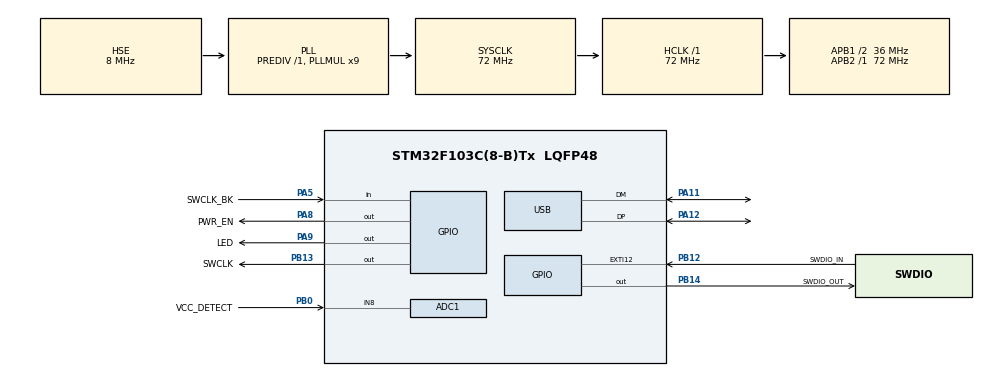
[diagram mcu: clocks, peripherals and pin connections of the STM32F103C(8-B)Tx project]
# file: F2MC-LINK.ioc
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ADC1.Channel-0\#ChannelRegularConversion=ADC_CHANNEL_8
ADC1.ContinuousConvMode=ENABLE
ADC1.NbrOfConversionFlag=1
ADC1.Rank-0\#ChannelRegularConversion=1
ADC1.SamplingTime-0\#ChannelRegularConversion=ADC_SAMPLETIME_71CYCLES_5
ADC1.master=1
Mcu.Family=STM32F1
Mcu.Name=STM32F103C(8-B)Tx
Mcu.Package=LQFP48
NVIC.EXTI15_10_IRQn=true\:0\:0\:false\:false\:true\:false\:true\:true\:true
NVIC.PriorityGroup=NVIC_PRIORITYGROUP_4
NVIC.USB_LP_CAN1_RX0_IRQn=true\:0\:0\:false\:false\:true\:false\:false\:true\:true
PA11.Mode=Device
PA11.Signal=USB_DM
PA12.Mode=Device
PA12.Signal=USB_DP
PA13.Mode=Serial_Wire
PA13.Signal=SYS_JTMS-SWDIO
PA14.Mode=Serial_Wire
PA14.Signal=SYS_JTCK-SWCLK
PA5.GPIO_Label=SWCLK_BK
PA5.Signal=GPIO_Input
PA8.GPIO_Label=PWR_EN
PA8.PinState=GPIO_PIN_RESET
PA8.Signal=GPIO_Output
PA9.GPIO_Label=LED
PA9.GPIO_Speed=GPIO_SPEED_FREQ_HIGH
PA9.Signal=GPIO_Output
PB0.GPIO_Label=VCC_DETECT
PB0.Signal=ADCx_IN8
PB12.GPIO_Label=SWDIO_IN
PB12.GPIO_ModeDefaultEXTI=GPIO_MODE_IT_FALLING
PB12.Signal=GPXTI12
PB13.GPIO_Label=SWCLK
PB13.GPIO_Speed=GPIO_SPEED_FREQ_HIGH
PB13.PinState=GPIO_PIN_SET
PB13.Signal=GPIO_Output
PB14.GPIO_Label=SWDIO_OUT
PB14.GPIO_Speed=GPIO_SPEED_FREQ_HIGH
PB14.PinState=GPIO_PIN_SET
PB14.Signal=GPIO_Output
PD0-OSC_IN.Mode=HSE-External-Oscillator
PD0-OSC_IN.Signal=RCC_OSC_IN
PD1-OSC_OUT.Mode=HSE-External-Oscillator
PD1-OSC_OUT.Signal=RCC_OSC_OUT
ProjectManager.HeapSize=0x200
ProjectManager.StackSize=0x400
ProjectManager.TargetToolchain=STM32CubeIDE
RCC.ADCPresc=RCC_ADCPCLK2_DIV6
RCC.AHBFreq_Value=72000000
RCC.APB1CLKDivider=RCC_HCLK_DIV2
RCC.APB1Freq_Value=36000000
RCC.APB1TimFreq_Value=72000000
RCC.APB2Freq_Value=72000000
RCC.APB2TimFreq_Value=72000000
RCC.HCLKFreq_Value=72000000
RCC.PLLMUL=RCC_PLL_MUL9
RCC.SYSCLKFreq_VALUE=72000000
RCC.SYSCLKSource=RCC_SYSCLKSOURCE_PLLCLK
RCC.USBFreq_Value=48000000
RCC.USBPrescaler=RCC_USBCLKSOURCE_PLL_DIV1_5
RealThread.X-CUBE-RT-Thread_Nano.4.1.1.RTAaThreadCcRTOSJjdevice=true
RealThread.X-CUBE-RT-Thread_Nano.4.1.1.RTAaThreadCcRTOSJjkernel=true
RealThread.X-CUBE-RT-Thread_Nano.4.1.1.RTAaThreadCcRTOSJjlibcpu=true
RealThread.X-CUBE-RT-Thread_Nano.4.1.1.RT_NAME_MAX=16
RealThread.X-CUBE-RT-Thread_Nano.4.1.1.RT_THREAD_PRIORITY_MAX=256
RealThread.X-CUBE-RT-Thread_Nano.4.1.1.RT_USING_MAILBOX=1
SH.ADCx_IN8.0=ADC1_IN8,IN8
USB_DEVICE.CLASS_NAME_FS=CUSTOM_HID
USB_DEVICE.VirtualMode=CustomHid
USB_DEVICE.VirtualModeFS=Custom_Hid_FS
VP_RealThread.X-CUBE-RT-Thread_Nano_VS_RTOSJjRTAaThread_4.1.1_4.1.1.Mode=RTOSJjRTAaThread
VP_USB_DEVICE_VS_USB_DEVICE_CUSTOM_HID_FS.Mode=CUSTOM_HID_FS
board=custom

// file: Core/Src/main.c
/* USER CODE BEGIN Header */
/**
  ******************************************************************************
  * @file           : main.c
  * @brief          : Main program body
  ******************************************************************************
  * @attention
  *
  * Copyright (c) 2026 STMicroelectronics.
  * All rights reserved.
  *
  * This software is licensed under terms that can be found in the LICENSE file
  * in the root directory of this software component.
  * If no LICENSE file comes with this software, it is provided AS-IS.
  *
  ******************************************************************************
  */
/* USER CODE END Header */
#include "main.h"
#include "adc.h"
#include "usb_device.h"
#include "gpio.h"

/* USER CODE BEGIN Includes */
#include <rtthread.h>
extern int rtthread_startup(void);   /* RT-Thread/board.c 提供 */
/* USER CODE END Includes */

void SystemClock_Config(void);

int main(void)
{

  /* USER CODE BEGIN 1 */
  /* ⚠ 关键：HAL_Init 会立即使能 SysTick 中断，而 pack 的 SysTick_Handler
   * (bsp/_template/cubemx_config/board.c) 中 rt_tick_increase() 会解引用
   * rt_current_thread——调度器启动前其为 NULL，必然 HardFault。
   * 故在 HAL_Init 之前屏蔽全局中断；MX_* 初始化均不依赖中断（USB 枚举可等待）。
   * rtthread_startup() 首次上下文切换时由 context_gcc.S 的 CPSIE I 恢复中断，
   * 此时 rt_current_thread 已有效。 */
  __disable_irq();
  /* USER CODE END 1 */

  /* MCU Configuration--------------------------------------------------------*/

  /* Reset of all peripherals, Initializes the Flash interface and the Systick. */
  HAL_Init();

  /* Configure the system clock */
  SystemClock_Config();

  /* Initialize all configured peripherals */
  MX_GPIO_Init();
  MX_ADC1_Init();
  MX_USB_DEVICE_Init();
  /* USER CODE BEGIN 2 */
  /* RT-Thread Nano 启动（不返回）：board.c rt_hw_board_init() →
   * App/prog_tasks.c rt_application_init() → 启动调度器 */
  rtthread_startup();
  /* USER CODE END 2 */

  /* Infinite loop */
  while (1)
  {

  }
}

void SystemClock_Config(void)
{
  RCC_OscInitTypeDef RCC_OscInitStruct = {0};
  RCC_ClkInitTypeDef RCC_ClkInitStruct = {0};
  RCC_PeriphCLKInitTypeDef PeriphClkInit = {0};

  /** Initializes the RCC Oscillators according to the specified parameters
  * in the RCC_OscInitTypeDef structure.
  */
  RCC_OscInitStruct.OscillatorType = RCC_OSCILLATORTYPE_HSE;
  RCC_OscInitStruct.HSEState = RCC_HSE_ON;
  RCC_OscInitStruct.HSEPredivValue = RCC_HSE_PREDIV_DIV1;
  RCC_OscInitStruct.HSIState = RCC_HSI_ON;
  RCC_OscInitStruct.PLL.PLLState = RCC_PLL_ON;
  RCC_OscInitStruct.PLL.PLLSource = RCC_PLLSOURCE_HSE;
  RCC_OscInitStruct.PLL.PLLMUL = RCC_PLL_MUL9;
  if (HAL_RCC_OscConfig(&RCC_OscInitStruct) != HAL_OK)
  {
    Error_Handler();
  }

  /** Initializes the CPU, AHB and APB buses clocks
  */
  RCC_ClkInitStruct.ClockType = RCC_CLOCKTYPE_HCLK|RCC_CLOCKTYPE_SYSCLK
                              |RCC_CLOCKTYPE_PCLK1|RCC_CLOCKTYPE_PCLK2;
  RCC_ClkInitStruct.SYSCLKSource = RCC_SYSCLKSOURCE_PLLCLK;
  RCC_ClkInitStruct.AHBCLKDivider = RCC_SYSCLK_DIV1;
  RCC_ClkInitStruct.APB1CLKDivider = RCC_HCLK_DIV2;
  RCC_ClkInitStruct.APB2CLKDivider = RCC_HCLK_DIV1;

  if (HAL_RCC_ClockConfig(&RCC_ClkInitStruct, FLASH_LATENCY_2) != HAL_OK)
  {
    Error_Handler();
  }
  PeriphClkInit.PeriphClockSelection = RCC_PERIPHCLK_ADC|RCC_PERIPHCLK_USB;
  PeriphClkInit.AdcClockSelection = RCC_ADCPCLK2_DIV6;
  PeriphClkInit.UsbClockSelection = RCC_USBCLKSOURCE_PLL_DIV1_5;
  if (HAL_RCCEx_PeriphCLKConfig(&PeriphClkInit) != HAL_OK)
  {
    Error_Handler();
  }
}

void Error_Handler(void)
{
  __disable_irq();
  while (1)
  {
  }
}
